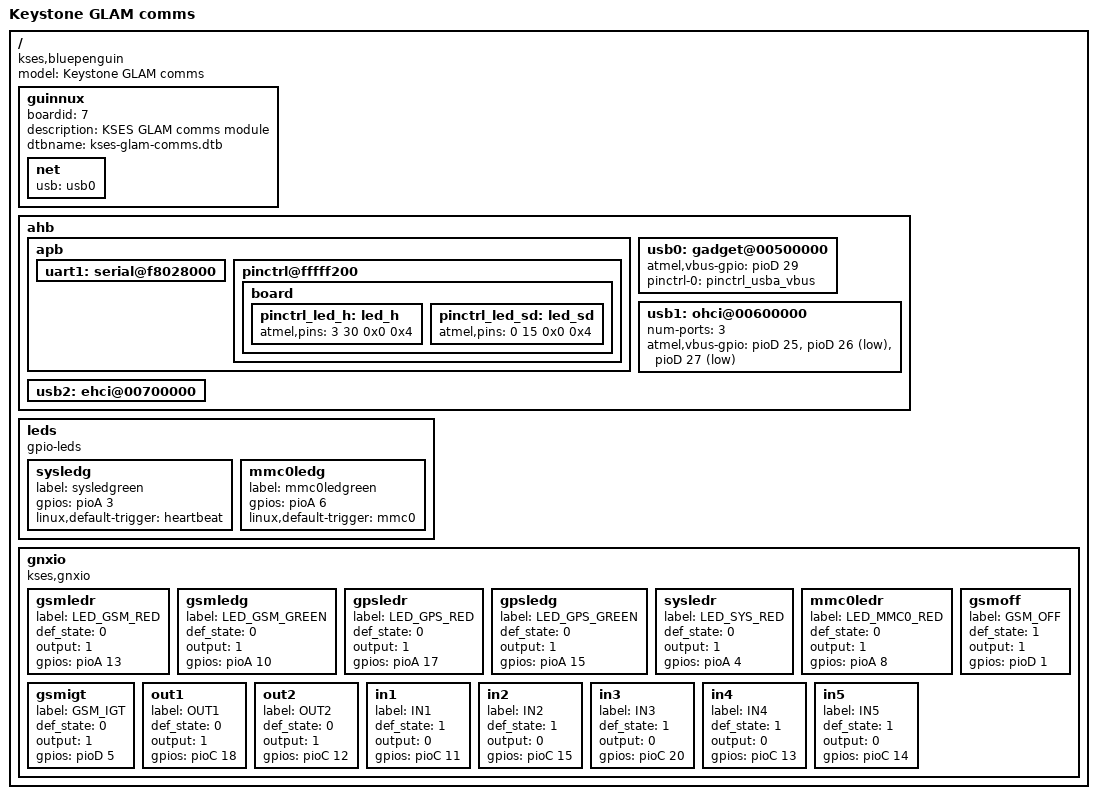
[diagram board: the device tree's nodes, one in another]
/*
 * kses-glam-comms.dts - Device Tree file for Keystone RSM Blue board
 *
 * Based on sama5d36ek.dtb by  Josh Wu <josh.wu@atmel.com> 
 *   Copyright (C) 2016 Keystone Electronic Solutions,
 *                2016 John Eigelaar <john@kses.net>
 *
 * Licensed under GPLv2 or later.
 */


/dts-v1/;

#include "sama5d36.dtsi"
#include "kses-bp-cm.dtsi"

/ {
	model = "Keystone GLAM comms";
    compatible = "kses,bluepenguin", "atmel,sama5d36ek", "atmel,sama5d3xmb", "atmel,sama5d3xcm", "atmel,sama5d36", "atmel,sama5d3", "atmel,sama5";

		
	guinnux {
		boardid = "7";
		description = "KSES GLAM comms module";	
		dtbname = "kses-glam-comms.dtb";
			
		net {
		        usb  = "usb0";
	    	};	    	
	};


	ahb {
		apb {			
			
			uart1: serial@f8028000 {
				pinctrl-names = "default";
				status = "okay";
			};
						
			pinctrl@fffff200 {
				board {
					pinctrl_led_h: led_h {
						atmel,pins =
							<3 30 0x0 0x4>;	/* PD30 GPIO  */
					};
					
					pinctrl_led_sd: led_sd {
						atmel,pins =
							<0 15 0x0 0x4>;	/* PA15 GPIO  */
					};
				};
			};
										
		};

		usb0: gadget@00500000 {
			atmel,vbus-gpio = <&pioD 29 0>;
			pinctrl-names = "default";
			pinctrl-0 = <&pinctrl_usba_vbus>;
			status = "okay";
		};

		usb1: ohci@00600000 {
			num-ports = <3>;
			atmel,vbus-gpio = <&pioD 25 0
					   &pioD 26 1
					   &pioD 27 1
					  >;
			status = "okay";
		};

		usb2: ehci@00700000 {
			status = "okay";
		};
	};

	leds {
		compatible = "gpio-leds";		

		sysledg {
			label = "sysledgreen";
			gpios = <&pioA 3 0>;	
			linux,default-trigger = "heartbeat";
		};
		
		mmc0ledg {
			label = "mmc0ledgreen";
			gpios = <&pioA 6 0>;	
			linux,default-trigger = "mmc0";
		};
	};
	
	 gnxio {
    	 compatible = "kses,gnxio";
    	     

    	 gsmledr {
    	        label = "LED_GSM_RED";
    	        def_state = <0>;
    	        output = <1>;
    	        gpios = <&pioA 13 0>;
    	     };
    	     
	 gsmledg {
    	        label = "LED_GSM_GREEN";
    	        def_state = <0>;
    	        output = <1>;
    	        gpios = <&pioA 10 0>;
    	     };    
    	     
	gpsledr {
    	        label = "LED_GPS_RED";
    	        def_state = <0>;
    	        output = <1>;
    	        gpios = <&pioA 17 0>;
    	     }; 
    	     
	gpsledg {
    	        label = "LED_GPS_GREEN";
    	        def_state = <0>;
    	        output = <1>;
    	        gpios = <&pioA 15 0>;
    	     }; 
    	         	     
    	 
    	 sysledr {
    	        label = "LED_SYS_RED";
    	        def_state = <0>;
    	        output = <1>;
    	        gpios = <&pioA 4 0>;
    	     };  
    	     
	mmc0ledr {
    	        label = "LED_MMC0_RED";
    	        def_state = <0>;
    	        output = <1>;
    	        gpios = <&pioA 8 0>;
    	     }; 
    	     
	gsmoff {
			label = "GSM_OFF";
			def_state = <1>;
			output = <1>;
			gpios = <&pioD 1 0>;
		};  	 
		
	gsmigt {
			label = "GSM_IGT";
			def_state = <0>;
			output = <1>;
			gpios = <&pioD 5 0>;
		};  	
			     
	out1 {
    	     label = "OUT1";
    	     def_state = <0>;
    	     output = <1>;
    	     gpios = <&pioC 18 0>;
    	 };

	out2 {
    	     label = "OUT2";
    	     def_state = <0>;
    	     output = <1>;
    	     gpios = <&pioC 12 0>;
    	 };	
    	 
	in1 {
    	        label = "IN1";
    	        def_state = <1>;
    	        output = <0>;
    	        gpios = <&pioC 11 0>;
	};
	
	in2 {
    	        label = "IN2";
    	        def_state = <1>;
    	        output = <0>;
    	        gpios = <&pioC 15 0>;
    	     };    
    	     
	in3 {
    	        label = "IN3";
    	        def_state = <1>;
    	        output = <0>;
    	        gpios = <&pioC 20 0>;
    	     };  
    	     
	in4 {
    	        label = "IN4";
    	        def_state = <1>;
    	        output = <0>;
    	        gpios = <&pioC 13 0>;
    	     };  
    	     
	in5 {
    	        label = "IN5";
    	        def_state = <1>;
    	        output = <0>;
    	        gpios = <&pioC 14 0>;
    	     };  

     };
	
};
